# MKW21Z4 register map
Vendor: Freescale Semiconductor, Inc.; Series: Kinetis_W; File version: 1.6
CPU: CM0PLUS r0p0, little endian, no MPU, no FPU, VTOR, 2 interrupt priority bits
Registers are 16-bit, read-write, no defined reset value unless marked. A register's access mark holds for its fields unless they carry their own. Offsets are from the block's base; [hi:lo] are bit positions; 'fields as' and 'values as' point back to an identical list.

## PLL_DIG_REGS — XCVR_PLL_DIG
Base 0x4005C224
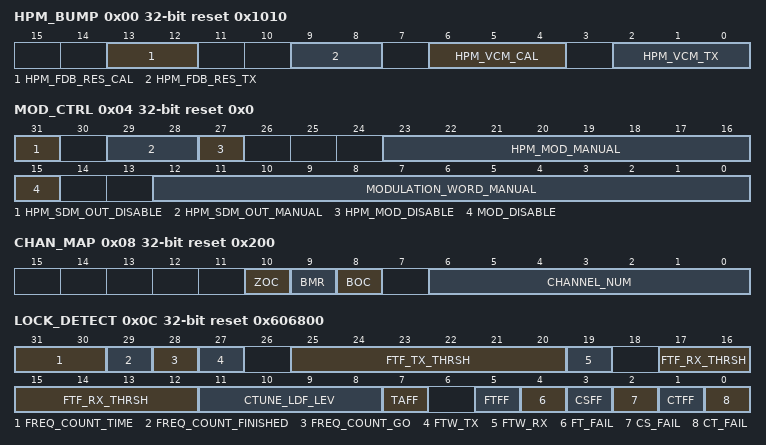
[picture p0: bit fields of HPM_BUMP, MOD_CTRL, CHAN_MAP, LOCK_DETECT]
0x00 HPM_BUMP 32-bit reset 0x1010 — PLL HPM Analog Bump Control
  [13:12] HPM_FDB_RES_CAL — rfctrl_tx_dac_bump_fdb_res[1:0] during Calibration
    0=29 kohms; 1=58 kohms(gain of 2); 2=13 kohms; 3=23.7 kohms
  [9:8] HPM_FDB_RES_TX — rfctrl_tx_dac_bump_fdb_res[1:0] during Transmission
    0=29 kohms; 1=58 kohms(gain of 2); 2=13 kohms; 3=23.7 kohms
  [6:4] HPM_VCM_CAL — rfctrl_tx_dac_bump_vcm[2:0] during Calibration
    0=432 mV; 1=328 mV; 2=456 mV; 3=473 mV; 4=488 mV; 5=408 mV; 6=392 mV; 7=376 mV
  [2:0] HPM_VCM_TX — rfctrl_tx_dac_bump_vcm[2:0] during Transmission
    values as HPM_VCM_CAL
0x04 MOD_CTRL 32-bit reset 0x0 — PLL Modulation Control
  [31] HPM_SDM_OUT_DISABLE — Disable HPM SDM out
  [29:28] HPM_SDM_OUT_MANUAL — Manual HPM SDM out
  [27] HPM_MOD_DISABLE — Disable HPM Modulation
  [23:16] HPM_MOD_MANUAL — Manual HPM Modulation
  [15] MOD_DISABLE — Disable Modulation Word
  [12:0] MODULATION_WORD_MANUAL — Manual Modulation Word
0x08 CHAN_MAP 32-bit reset 0x200 — PLL Channel Mapping
  [10] ZOC — 802.15.4 Channel Number Override
    0=802.15.4 channel number comes from the 802.15.4 Link Layer; 1=802.15.4 channel number comes from the CHANNEL_NUM register (802.15.4 protocols 4 and 5)
  [9] BMR — BLE MBAN Channel Remap
    0=BLE channel 39 is mapped to BLE channel 39, 2.480 GHz; 1=BLE channel 39 is mapped to MBAN channel 39, 2.399 GHz
  [8] BOC — BLE Channel Number Override
    0=BLE channel number comes from the BLE Link Layer; 1=BLE channel number comes from the CHANNEL_NUM register (BLE protocols 0 and 2)
  [6:0] CHANNEL_NUM — Protocol specific Channel Number for PLL Frequency Mapping
0x0C LOCK_DETECT 32-bit reset 0x606800 — PLL Lock Detect Control
  [31:30] FREQ_COUNT_TIME — Frequency Meter Count Time
    0=10 us; 1=25 us; 2=50 us; 3=100 us
  [29] FREQ_COUNT_FINISHED ro — Frequency Meter has finished the Count Time
  [28] FREQ_COUNT_GO — Start the Frequency Meter
  [27] FTW_TX — TX Frequency Target Window time select
    0=4 us; 1=8 us
  [25:20] FTF_TX_THRSH — TX Frequency Target Fail Threshold
  [19] FTW_RX — RX Frequency Target Window time select
    0=4 us; 1=8 us
  [17:12] FTF_RX_THRSH — RX Frequency Target Fail Threshold
  [11:8] CTUNE_LDF_LEV — CTUNE Lock Detect Fail Level
  [7] TAFF — TSM Abort Failure Flag
  [5] FTFF — Frequency Target Failure Flag
  [4] FT_FAIL ro — Real time status of Frequency Target Failure
  [3] CSFF — Cycle Slip Failure Flag, held until cleared
  [2] CS_FAIL ro — Real time status of Cycle Slip circuit
  [1] CTFF — CTUNE Failure Flag, held until cleared
  [0] CT_FAIL ro — Real time status of Coarse Tune Fail signal
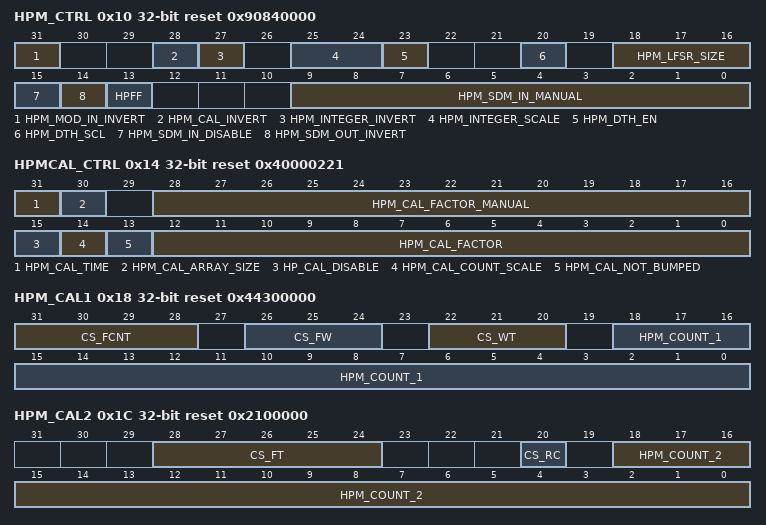
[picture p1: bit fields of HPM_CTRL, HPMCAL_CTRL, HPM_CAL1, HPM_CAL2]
0x10 HPM_CTRL 32-bit reset 0x90840000 — PLL High Port Modulator Control
  [31] HPM_MOD_IN_INVERT — Invert High Port Modulation
  [28] HPM_CAL_INVERT — Invert High Port Modulator Calibration
  [27] HPM_INTEGER_INVERT — Invert High Port Modulation Integer
  [25:24] HPM_INTEGER_SCALE — High Port Modulation Integer Scale
    0=No Scaling; 1=Multiply by 2; 2=Divide by 2
  [23] HPM_DTH_EN — Dither Enable for HPM LFSR
  [20] HPM_DTH_SCL — HPM Dither Scale
  [18:16] HPM_LFSR_SIZE — HPM LFSR Length
    0=LFSR 9, tap mask 100010000; 1=LFSR 10, tap mask 1001000000; 2=LFSR 11, tap mask 11101000000; 3=LFSR 13, tap mask 1101100000000; 4=LFSR 15, tap mask 111010000000000; 5=LFSR 17, tap mask 11110000000000000
  [15] HPM_SDM_IN_DISABLE — Disable HPM SDM Input
  [14] HPM_SDM_OUT_INVERT — Invert HPM SDM Output
  [13] HPFF — HPM SDM Invalid Flag
  [9:0] HPM_SDM_IN_MANUAL — Manual High Port SDM Fractional value
0x14 HPMCAL_CTRL 32-bit reset 0x40000221 — PLL High Port Calibration Control
  [31] HPM_CAL_TIME — High Port Modulation Calibration Time
    0=25 us; 1=50 us
  [30] HPM_CAL_ARRAY_SIZE — High Port Modulation Calibration Array Size
    0=128; 1=256
  [28:16] HPM_CAL_FACTOR_MANUAL — Manual HPM Calibration Factor
  [15] HP_CAL_DISABLE — Disable HPM Manual Calibration
  [14] HPM_CAL_COUNT_SCALE
  [13] HPM_CAL_NOT_BUMPED
  [12:0] HPM_CAL_FACTOR ro — High Port Modulation Calibration Factor
0x18 HPM_CAL1 32-bit reset 0x44300000 — PLL High Port Calibration Result 1
  [31:28] CS_FCNT — Cycle Slip Flag Count
  [26:24] CS_FW — Cycle Slip Flag Window
    0=8 us; 1=16 us; 2=24 us; 3=32 us; 4=64 us; 5=96 us; 6=128 us; 7=256 us
  [22:20] CS_WT — Cycle Slip Wait Time
    0=128 us; 1=256 us; 2=384 us; 3=512 us; 4=640 us; 5=768 us; 6=896 us; 7=1024 us
  [18:0] HPM_COUNT_1 ro — High Port Modulation Counter Value 1
0x1C HPM_CAL2 32-bit reset 0x2100000 — PLL High Port Calibration Result 2
  [28:24] CS_FT — Cycle Slip Flag Timeout
  [20] CS_RC — Cycle Slip Recycle
  [18:0] HPM_COUNT_2 ro — High Port Modulation Counter Value 2
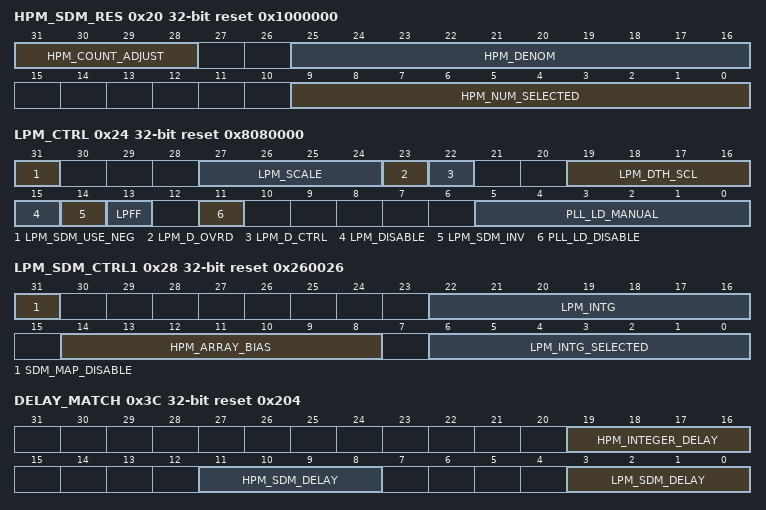
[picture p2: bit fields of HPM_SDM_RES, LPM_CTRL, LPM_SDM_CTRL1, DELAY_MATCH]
0x20 HPM_SDM_RES 32-bit reset 0x1000000 — PLL High Port Sigma Delta Results
  [31:28] HPM_COUNT_ADJUST
  [25:16] HPM_DENOM — High Port Modulator SDM Denominator
  [9:0] HPM_NUM_SELECTED ro — High Port Modulator SDM Numerator
0x24 LPM_CTRL 32-bit reset 0x8080000 — PLL Low Port Modulator Control
  [31] LPM_SDM_USE_NEG — Use the Negedge of the Sigma Delta clock
  [27:24] LPM_SCALE — LPM Scale Factor
    0=No Scaling; 1=Multiply by 2; 2=Multiply by 4; 3=Multiply by 8; 4=Multiply by 16; 5=Multiply by 32; 6=Multiply by 64; 7=Multiply by 128; 8=Multiply by 256; 9=Multiply by 512; 10=Multiply by 1024; 11=Multiply by 2048
  [23] LPM_D_OVRD — LPM Dither Override Mode Select
  [22] LPM_D_CTRL — LPM Dither Control in Override Mode
  [19:16] LPM_DTH_SCL — LPM Dither Scale
    5=-128 to 96; 6=-256 to 192; 7=-512 to 384; 8=-1024 to 768; 9=-2048 to 1536; 10=-4096 to 3072; 11=-8192 to 6144
  [15] LPM_DISABLE — Disable LPM SDM
  [14] LPM_SDM_INV — Invert LPM SDM
  [13] LPFF — LPM SDM Invalid Flag
  [11] PLL_LD_DISABLE — Disable PLL Loop Divider
  [5:0] PLL_LD_MANUAL — Manual PLL Loop Divider value
0x28 LPM_SDM_CTRL1 32-bit reset 0x260026 — PLL Low Port Sigma Delta Control 1
  [31] SDM_MAP_DISABLE — Disable SDM Mapping
  [22:16] LPM_INTG — Manual Low Port Modulation Integer Value
  [14:8] HPM_ARRAY_BIAS — Bias value for High Port DAC Array Midpoint
  [6:0] LPM_INTG_SELECTED ro — Low Port Modulation Integer Value Selected
0x2C LPM_SDM_CTRL2 32-bit reset 0x2000000 — PLL Low Port Sigma Delta Control 2
  [27:0] LPM_NUM — Low Port Modulation Numerator
0x30 LPM_SDM_CTRL3 32-bit reset 0x4000000 — PLL Low Port Sigma Delta Control 3
  [27:0] LPM_DENOM — Low Port Modulation Denominator
0x34 LPM_SDM_RES1 32-bit ro reset 0xE200000 — PLL Low Port Sigma Delta Result 1
  [27:0] LPM_NUM_SELECTED — Low Port Modulation Numerator Applied
0x38 LPM_SDM_RES2 32-bit ro reset 0x4000000 — PLL Low Port Sigma Delta Result 2
  [27:0] LPM_DENOM_SELECTED — Low Port Modulation Denominator Selected
0x3C DELAY_MATCH 32-bit reset 0x204 — PLL Delay Matching
  [19:16] HPM_INTEGER_DELAY — High Port Integer Delay Matching
  [11:8] HPM_SDM_DELAY — High Port SDM Delay Matching
  [3:0] LPM_SDM_DELAY — Low Port SDM Delay Matching
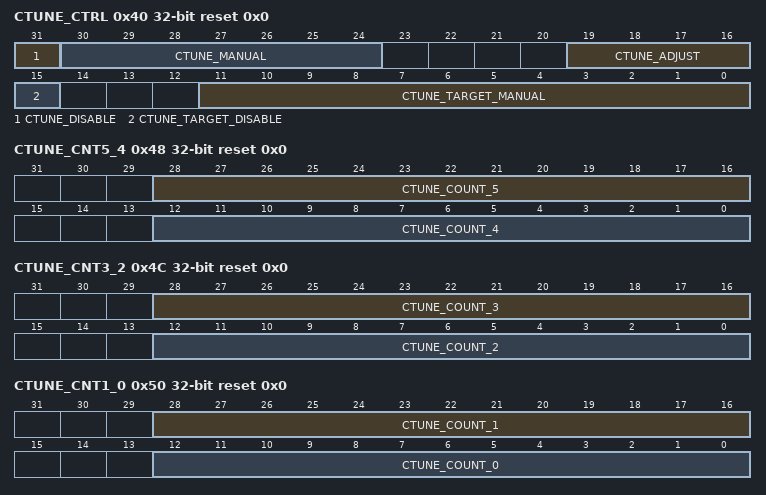
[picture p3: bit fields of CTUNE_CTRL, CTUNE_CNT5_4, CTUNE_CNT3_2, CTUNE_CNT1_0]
0x40 CTUNE_CTRL 32-bit reset 0x0 — PLL Coarse Tune Control
  [31] CTUNE_DISABLE — Coarse Tune Disable
  [30:24] CTUNE_MANUAL — Manual Coarse Tune Setting
  [19:16] CTUNE_ADJUST — Coarse Tune Count Adjustment
  [15] CTUNE_TARGET_DISABLE — Disable Coarse Tune Target
  [11:0] CTUNE_TARGET_MANUAL — Manual Coarse Tune Target
0x44 CTUNE_CNT6 32-bit ro reset 0x0 — PLL Coarse Tune Count 6
  [12:0] CTUNE_COUNT_6
0x48 CTUNE_CNT5_4 32-bit ro reset 0x0 — PLL Coarse Tune Counts 5 and 4
  [28:16] CTUNE_COUNT_5, [12:0] CTUNE_COUNT_4
0x4C CTUNE_CNT3_2 32-bit ro reset 0x0 — PLL Coarse Tune Counts 3 and 2
  [28:16] CTUNE_COUNT_3, [12:0] CTUNE_COUNT_2
0x50 CTUNE_CNT1_0 32-bit ro reset 0x0 — PLL Coarse Tune Counts 1 and 0
  [28:16] CTUNE_COUNT_1, [12:0] CTUNE_COUNT_0
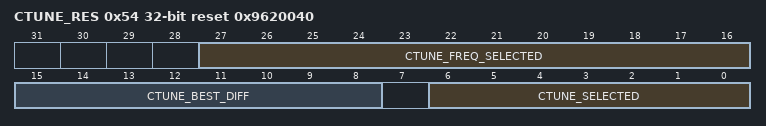
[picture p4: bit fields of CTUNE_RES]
0x54 CTUNE_RES 32-bit ro reset 0x9620040 — PLL Coarse Tune Results
  [27:16] CTUNE_FREQ_SELECTED — Coarse Tune Frequency Selected
  [15:8] CTUNE_BEST_DIFF — Coarse Tune Absolute Best Difference
  [6:0] CTUNE_SELECTED — Coarse Tune Setting to VCO
